VERSION "1"
BU_: VCU BMS GW
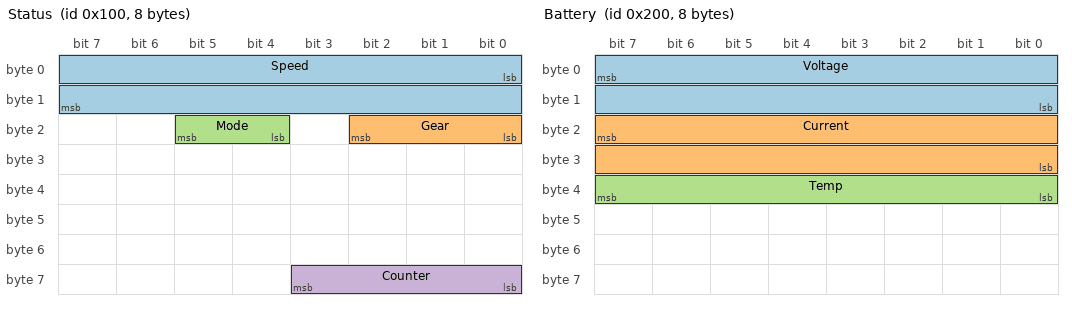
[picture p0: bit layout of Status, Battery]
BO_ 256 Status: 8 VCU
 SG_ Speed : 0|16@1+ (0.01,0) [0|655.35] "km/h" GW
 SG_ Gear : 16|3@1+ (1,0) [0|7] "" GW
 SG_ Mode : 20|2@1+ (1,0) [0|3] "" GW
 SG_ Counter : 56|4@1+ (1,0) [0|15] "" GW
BO_ 512 Battery: 8 BMS
 SG_ Voltage : 7|16@0+ (0.01,0) [0|655.35] "V" VCU
 SG_ Current : 23|16@0- (0.05,0) [-1638.4|1638.35] "A" VCU
 SG_ Temp : 39|8@0- (1,0) [-40|85] "degC" VCU
BO_ 768 Legacy: 2 GW
 SG_ OldFlag : 0|1@1+ (1,0) [0|1] "" VCU
BO_ 1024 Charger: 8 GW
 SG_ Limit : 0|16@1+ (0.1,0) [0|6553.5] "A" BMS
CM_ BO_ 256 "Vehicle status.";
VAL_ 256 Gear 0 "Park" 1 "Reverse" 2 "Neutral" 3 "Drive" ;
